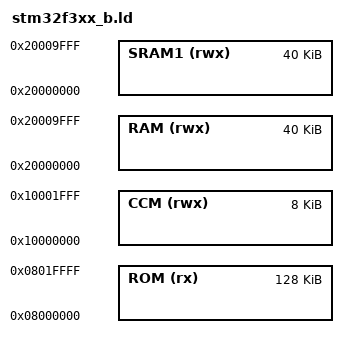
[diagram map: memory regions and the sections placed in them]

MEMORY
{
	ROM (rx)      : ORIGIN = 0x08000000, LENGTH = 128k
	RAM (rwx)     : ORIGIN = 0x20000000, LENGTH = 40k

	SRAM1 (rwx)   : ORIGIN = 0x20000000, LENGTH = 40k
	CCM (rwx)     : ORIGIN = 0x10000000, LENGTH = 8k
}

INCLUDE stm32_iccm.ld
